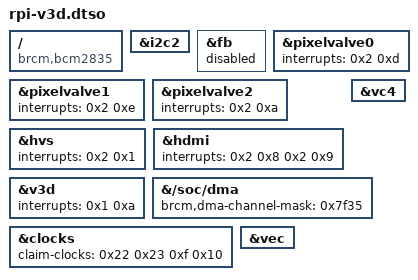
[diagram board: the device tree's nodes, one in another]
/dts-v1/;
/plugin/;

/ {
	compatible = "brcm,bcm2835", "brcm,bcm2708", "brcm,bcm2709";

	fragment@0 {
		target = <&i2c2>;

		__overlay__ {
			status = "okay";
		};
	};

	fragment@1 {
		target = <&fb>;

		__overlay__ {
			status = "disabled";
		};
	};

	fragment@2 {
		target = <&pixelvalve0>;

		__overlay__ {
			interrupts = <0x2 0xd>;
			status = "okay";
		};
	};

	fragment@3 {
		target = <&pixelvalve1>;

		__overlay__ {
			interrupts = <0x2 0xe>;
			status = "okay";
		};
	};

	fragment@4 {
		target = <&pixelvalve2>;

		__overlay__ {
			interrupts = <0x2 0xa>;
			status = "okay";
		};
	};

	fragment@5 {
		target = <&hvs>;

		__overlay__ {
			interrupts = <0x2 0x1>;
			status = "okay";
		};
	};

	fragment@6 {
		target = <&hdmi>;

		__overlay__ {
			interrupts = <0x2 0x8 0x2 0x9>;
			status = "okay";
		};
	};

	fragment@7 {
		target = <&v3d>;

		__overlay__ {
			interrupts = <0x1 0xa>;
			status = "okay";
		};
	};

	fragment@8 {
		target = <&vc4>;

		__overlay__ {
			status = "okay";
		};
	};

	fragment@9 {
		target-path = "/soc/dma";

		__overlay__ {
			brcm,dma-channel-mask = <0x7f35>;
		};
	};

	fragment@10 {
		target = <&clocks>;

		__overlay__ {
			claim-clocks = <0x22 0x23 0xf 0x10>;
		};
	};

	fragment@11 {
		target = <&vec>;

		__overlay__ {
			status = "okay";
		};
	};
};
